VERSION ""

NS_ :

BS_:

BU_:

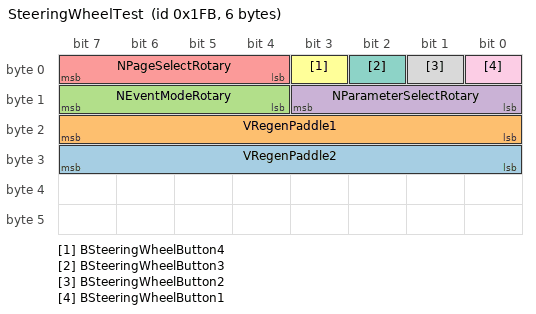
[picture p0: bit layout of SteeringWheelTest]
BO_ 507 SteeringWheelTest: 6 Vector__XXX
 SG_ VRegenPaddle2 : 24|8@1+ (0.0129,0) [0|3.2895] "" Vector__XXX
 SG_ VRegenPaddle1 : 16|8@1+ (0.0129,0) [0|3.2895] "" Vector__XXX
 SG_ NEventModeRotary : 12|4@1+ (1,1) [1|16] "" Vector__XXX
 SG_ NParameterSelectRotary : 8|4@1+ (1,1) [1|16] "" Vector__XXX
 SG_ NPageSelectRotary : 4|4@1+ (1,1) [1|16] "" Vector__XXX
 SG_ BSteeringWheelButton4 : 3|1@1+ (1,0) [0|1] "" Vector__XXX
 SG_ BSteeringWheelButton3 : 2|1@1+ (1,0) [0|1] "" Vector__XXX
 SG_ BSteeringWheelButton2 : 1|1@1+ (1,0) [0|1] "" Vector__XXX
 SG_ BSteeringWheelButton1 : 0|1@1+ (1,0) [0|1] "" Vector__XXX

BA_DEF_  "BusType" STRING ;
BA_DEF_DEF_  "BusType" "CAN";
